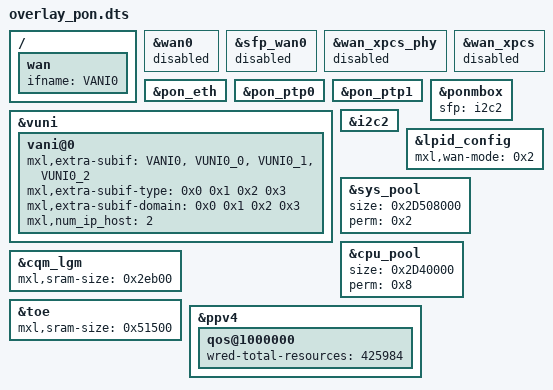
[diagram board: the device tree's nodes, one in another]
/dts-v1/;
/plugin/;

/ {
	fragment@0 {
		target-path = "/";
		__overlay__ {
			wan {
				ifname = "VANI0";
			};
		};
	};

	fragment@1 {
		target = <&wan0>;
		__overlay__ {
			status = "disabled";
		};
	};

	fragment@2 {
		target = <&sfp_wan0>;
		__overlay__ {
			status = "disabled";
		};
	};

	fragment@3 {
		target = <&wan_xpcs_phy>;
		__overlay__ {
			status = "disabled";
		};
	};

	 fragment@4 {
		target = <&wan_xpcs>;
		__overlay__ {
			status = "disabled";
		};
	};

	fragment@5 {
		target = <&pon_eth>;
		__overlay__ {
			status = "okay";
		};
	};

	fragment@6 {
		target = <&pon_ptp0>;
		__overlay__ {
			status = "okay";
		};
	};

	fragment@7 {
		target = <&pon_ptp1>;
		__overlay__ {
			status = "okay";
		};
	};
	
	fragment@8 {
		target = <&ponmbox>;
		__overlay__ {
			status = "okay";
			/* I2C bus to the optical WAN transceiver */
			sfp = <&i2c2>;
		};
	};
	
	fragment@9 {
		target = <&vuni>;
		__overlay__ {
			status = "okay";
			vani@0 {
				mxl,extra-subif = "VANI0", "VUNI0_0", "VUNI0_1", "VUNI0_2";
				mxl,extra-subif-type = <0x0 0x1 0x2 0x3>;
				mxl,extra-subif-domain = <0x0 0x1 0x2 0x3>;
				mxl,num_ip_host = <2>;
			};
		};
	};
	
	fragment@10 {
		target = <&i2c2>;
		__overlay__ {
			status = "okay";
		};
	};

	fragment@11 {
		target = <&lpid_config>;
		__overlay__ {
			mxl,wan-mode = <0x2>;
		};
	};

	fragment@12 {
		target = <&sys_pool>;
		__overlay__ {
			size = <0x2D508000>;
			perm = <0x2>;
		};
	};

	fragment@13 {
		target = <&cpu_pool>;
		__overlay__ {
			size = <0x2D40000>;
			perm = <0x8>;
		};
	};
	
	fragment@14 {
		target = <&cqm_lgm>;
		__overlay__ {
			mxl,sram-size = <0x2eb00>;
		};
	};
	
	fragment@15 {
		target = <&toe>;
		__overlay__ {
			mxl,sram-size = <0x51500>;
		};
	};
	
	fragment@16 {
		target = <&ppv4>;
		__overlay__ {
			qos@1000000 {
				wred-total-resources = <425984>;
			};
		};
	};
};
